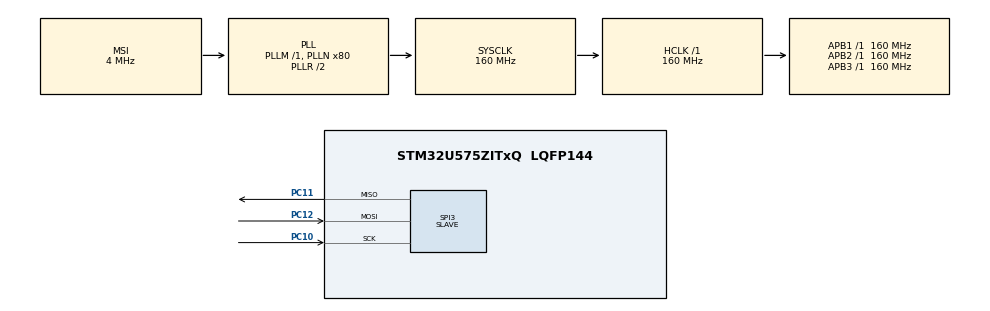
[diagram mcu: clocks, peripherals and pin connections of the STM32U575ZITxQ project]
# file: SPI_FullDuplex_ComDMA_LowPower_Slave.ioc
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CORTEX_M33_NS.userName=CORTEX_M33
LPDMA1.LINKALLOCATEDPORT_LPDMACH0=DMA_LINK_ALLOCATED_PORT1
LPDMA1.LINKALLOCATEDPORT_LPDMACH1=DMA_LINK_ALLOCATED_PORT1
LPDMA1.PRIORITY_LL_LPDMACH0=DMA_LOW_PRIORITY_HIGH_WEIGHT
LPDMA1.PRIORITY_LL_LPDMACH1=DMA_LOW_PRIORITY_HIGH_WEIGHT
Linkedlist.MDMA_Channel0.GP_SW.0.BlkHWRequest=DMA_BREQ_SINGLE_BURST
Linkedlist.MDMA_Channel0.GP_SW.0.DataHandling=NONE
Linkedlist.MDMA_Channel0.GP_SW.0.DataSize=0
Linkedlist.MDMA_Channel0.GP_SW.0.DestDataWidth=DMA_DEST_DATAWIDTH_BYTE
Linkedlist.MDMA_Channel0.GP_SW.0.DestInc=DMA_DINC_FIXED
Linkedlist.MDMA_Channel0.GP_SW.0.Direction=DMA_MEMORY_TO_PERIPH
Linkedlist.MDMA_Channel0.GP_SW.0.DstAddress=0
Linkedlist.MDMA_Channel0.GP_SW.0.Instance=MDMA_Channel0
Linkedlist.MDMA_Channel0.GP_SW.0.LL_MASTERDMA=LPDMA
Linkedlist.MDMA_Channel0.GP_SW.0.LL_NAME=Queue_tx
Linkedlist.MDMA_Channel0.GP_SW.0.LL_TYPE=LINEAR
Linkedlist.MDMA_Channel0.GP_SW.0.NODE_NAME=Node_tx
Linkedlist.MDMA_Channel0.GP_SW.0.Requestforcodegen=LPDMA1_REQUEST_SPI3_TX
Linkedlist.MDMA_Channel0.GP_SW.0.SrcAddress=0
Linkedlist.MDMA_Channel0.GP_SW.0.SrcDataWidth=DMA_SRC_DATAWIDTH_BYTE
Linkedlist.MDMA_Channel0.GP_SW.0.SrcInc=DMA_SINC_INCREMENTED
Linkedlist.MDMA_Channel0.GP_SW.0.TransferEventMode=DMA_TCEM_BLOCK_TRANSFER
Linkedlist.MDMA_Channel0.GP_SW.0.TriggerPolarity=DMA_TRIG_POLARITY_MASKED
Linkedlist.MDMA_Channel0.Request0=GP_SW
Linkedlist.MDMA_Channel0.RequestsNb=1
Linkedlist.MDMA_Channel1.GP_SW.0.BlkHWRequest=DMA_BREQ_SINGLE_BURST
Linkedlist.MDMA_Channel1.GP_SW.0.DataHandling=NONE
Linkedlist.MDMA_Channel1.GP_SW.0.DataSize=0
Linkedlist.MDMA_Channel1.GP_SW.0.DestDataWidth=DMA_DEST_DATAWIDTH_BYTE
Linkedlist.MDMA_Channel1.GP_SW.0.DestInc=DMA_DINC_INCREMENTED
Linkedlist.MDMA_Channel1.GP_SW.0.Direction=DMA_PERIPH_TO_MEMORY
Linkedlist.MDMA_Channel1.GP_SW.0.DstAddress=0
Linkedlist.MDMA_Channel1.GP_SW.0.Instance=MDMA_Channel1
Linkedlist.MDMA_Channel1.GP_SW.0.LL_MASTERDMA=LPDMA
Linkedlist.MDMA_Channel1.GP_SW.0.LL_NAME=Queue_rx
Linkedlist.MDMA_Channel1.GP_SW.0.LL_TYPE=LINEAR
Linkedlist.MDMA_Channel1.GP_SW.0.NODE_NAME=Node_rx
Linkedlist.MDMA_Channel1.GP_SW.0.Requestforcodegen=LPDMA1_REQUEST_SPI3_RX
Linkedlist.MDMA_Channel1.GP_SW.0.SrcAddress=0
Linkedlist.MDMA_Channel1.GP_SW.0.SrcDataWidth=DMA_SRC_DATAWIDTH_BYTE
Linkedlist.MDMA_Channel1.GP_SW.0.SrcInc=DMA_SINC_FIXED
Linkedlist.MDMA_Channel1.GP_SW.0.TransferEventMode=DMA_TCEM_BLOCK_TRANSFER
Linkedlist.MDMA_Channel1.GP_SW.0.TriggerPolarity=DMA_TRIG_POLARITY_MASKED
Linkedlist.MDMA_Channel1.Request0=GP_SW
Linkedlist.MDMA_Channel1.RequestsNb=1
Linkedlist.RequestSet0=MDMA_Channel0
Linkedlist.RequestSet1=MDMA_Channel1
Linkedlist.RequestSetsNb=2
Mcu.Family=STM32U5
Mcu.Name=STM32U575ZITxQ
Mcu.Package=LQFP144
NVIC.LPDMA1_Channel0_IRQn=true\:0\:0\:false\:false\:true\:true\:true\:true
NVIC.LPDMA1_Channel1_IRQn=true\:0\:0\:false\:false\:true\:true\:true\:true
NVIC.PriorityGroup=NVIC_PRIORITYGROUP_4
NVIC.SPI3_IRQn=true\:0\:0\:false\:false\:true\:true\:true\:true
PC10.Mode=Full_Duplex_Slave
PC10.Signal=SPI3_SCK
PC11.Mode=Full_Duplex_Slave
PC11.Signal=SPI3_MISO
PC12.Mode=Full_Duplex_Slave
PC12.Signal=SPI3_MOSI
PWR.PowerMode=PWR_SMPS_SUPPLY
ProjectManager.HeapSize=0x200
ProjectManager.StackSize=0x400
ProjectManager.TargetToolchain=EWARM V8.50
RCC.ADCFreq_Value=16000000
RCC.AHBFreq_Value=160000000
RCC.APB1Freq_Value=160000000
RCC.APB1TimFreq_Value=160000000
RCC.APB2Freq_Value=160000000
RCC.APB2TimFreq_Value=160000000
RCC.APB3Freq_Value=160000000
RCC.CortexFreq_Value=160000000
RCC.DACCLockSelectionVirtual=RCC_DAC1CLKSOURCE_LSI
RCC.DACCLockSelectionVirtualString=RCC_DAC1CLKSOURCE_LSI
RCC.EPOD_VALUE=4000000
RCC.HCLKFreq_Value=160000000
RCC.HSE_VALUE=16000000
RCC.HSI48_VALUE=48000000
RCC.HSI_VALUE=16000000
RCC.LSE_VALUE=32768
RCC.LSIDIV_VALUE=32000
RCC.MSI_VALUE=4000000
RCC.PLLN=80
RCC.SPI3CLockSelection=RCC_SPI3CLKSOURCE_HSI
RCC.SYSCLKFreq_VALUE=160000000
RCC.SYSCLKSource=RCC_SYSCLKSOURCE_PLLCLK
RCC.USBFreq_Value=48000000
RCC.VCOOutputFreq_Value=320000000
SPI3.DataSize=SPI_DATASIZE_8BIT
SPI3.Direction=SPI_DIRECTION_2LINES
SPI3.Mode=SPI_MODE_SLAVE
SPI3.VirtualType=VM_SLAVE
VP_ICACHE_VS_ICACHE.Mode=DirectMappedCache
VP_LPBAMQUEUE_VS_QUEUE.Mode=QUEUEMODE
VP_LPBAM_VS_SIG1.Mode=SmartRun
VP_LPBAM_VS_SIG4.Mode=LPDMA1
VP_LPDMA1_VS_LPDMACH0.Mode=LINKEDLIST_LPDMACH0
VP_LPDMA1_VS_LPDMACH1.Mode=LINKEDLIST_LPDMACH1
VP_PWR_VS_DBSignals.Mode=DisableDeadBatterySignals
VP_PWR_VS_LPOM.Mode=PowerOptimisation
VP_PWR_VS_SECSignals.Mode=Security/Privilege
board=custom

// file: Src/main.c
/* USER CODE BEGIN Header */
/**
  ******************************************************************************
  * @file           : main.c
  * @brief          : Main program body
  ******************************************************************************
  * @attention
  *
  * Copyright (c) 2021 STMicroelectronics.
  * All rights reserved.
  *
  * This software is licensed under terms that can be found in the LICENSE file
  * in the root directory of this software component.
  * If no LICENSE file comes with this software, it is provided AS-IS.
  *
  ******************************************************************************
  */
/* USER CODE END Header */
#include "main.h"

/* USER CODE BEGIN PTD */
enum {
	TRANSFER_WAIT,
	TRANSFER_COMPLETE,
	TRANSFER_ERROR
};
/* USER CODE END PTD */

/* USER CODE BEGIN PD */
uint8_t aTxBuffer[] = "****SPI - Two Boards communication based on DMA **** SPI Message ******** SPI Message ******** SPI Message ****";

/* Buffer used for reception */
#define BUFFER_ALIGNED_SIZE (((BUFFERSIZE+31)/32)*32)
ALIGN_32BYTES(uint8_t aRxBuffer[BUFFER_ALIGNED_SIZE]);

/* transfer state */
__IO uint32_t wTransferState = TRANSFER_WAIT;
/* USER CODE END PD */

DMA_HandleTypeDef handle_LPDMA1_Channel0;
DMA_HandleTypeDef handle_LPDMA1_Channel1;

SPI_HandleTypeDef hspi3;

void SystemClock_Config(void);
static void SystemPower_Config(void);
static void MX_GPIO_Init(void);
static void MX_LPDMA1_Init(void);
static void MX_ICACHE_Init(void);
static void MX_SPI3_Init(void);
/* USER CODE BEGIN PFP */
static uint16_t Buffercmp(uint8_t *pBuffer1, uint8_t *pBuffer2, uint16_t BufferLength);
/* USER CODE END PFP */

int main(void)
{

  /* USER CODE BEGIN 1 */
  /* STM32U5xx HAL library initialization:
       - Configure the Flash prefetch
       - Configure the Systick to generate an interrupt each 1 msec
       - Set NVIC Group Priority to 3
       - Low Level Initialization
     */
  /* USER CODE END 1 */

  /* MCU Configuration--------------------------------------------------------*/

  /* Reset of all peripherals, Initializes the Flash interface and the Systick. */
  HAL_Init();

  /* Configure the System Power */
  SystemPower_Config();

  /* Configure the system clock */
  SystemClock_Config();

  /* USER CODE BEGIN SysInit */
  /* Configure LED1, LED2 and LED3 */
  BSP_LED_Init(LED1);
  BSP_LED_Init(LED2);
  BSP_LED_Init(LED3);
  /* USER CODE END SysInit */

  /* Initialize all configured peripherals */
  MX_GPIO_Init();
  MX_LPDMA1_Init();
  MX_ICACHE_Init();
  MX_SPI3_Init();
  /* USER CODE BEGIN 2 */
  MX_Queue_tx_Config();
  HAL_DMAEx_List_LinkQ(&handle_LPDMA1_Channel1, &Queue_tx);
  __HAL_LINKDMA(&hspi3, hdmatx, handle_LPDMA1_Channel1);
  MX_Queue_rx_Config();
  HAL_DMAEx_List_LinkQ(&handle_LPDMA1_Channel0, &Queue_rx);
  __HAL_LINKDMA(&hspi3, hdmarx, handle_LPDMA1_Channel0);

  /*##-2- Start the Full Duplex Communication process ########################*/
  /* While the SPI in TransmitReceive process, user can transmit data through
     "aTxBuffer" buffer & receive data through "aRxBuffer" */
  if(HAL_SPI_TransmitReceive_DMA(&hspi3, (uint8_t*)aTxBuffer, (uint8_t *)aRxBuffer, BUFFERSIZE) != HAL_OK)
  {
    /* Transfer error in transmission process */
    Error_Handler();
  }

  /* Disable the SPI Error Interrupt Bit */
  __HAL_SPI_DISABLE_IT(&hspi3, (SPI_IT_OVR | SPI_IT_UDR | SPI_IT_FRE | SPI_IT_MODF));

  /* Enable the SPI End Of transfer Interrupt Bit */
  __HAL_SPI_ENABLE_IT(&hspi3, SPI_IT_EOT);

  /* Enter the system to stop 2 mode */
  HAL_PWREx_EnterSTOP2Mode(PWR_STOPENTRY_WFE);

  /* Check that the system was resumed from stop 2 */
  if ((READ_BIT(PWR->CR1, PWR_CR1_LPMS) != PWR_CR1_LPMS_1) || \
    (__HAL_PWR_GET_FLAG(PWR_FLAG_STOPF) == 0U))
  {
    while(1); /* KO */
  }
  /* Clear stop flag */
  __HAL_PWR_CLEAR_FLAG(PWR_FLAG_STOPF);

  /* Check that stop flag is cleared */
  if (__HAL_PWR_GET_FLAG(PWR_FLAG_STOPF) != 0U)
  {
    while(1); /* KO */
  }

  /*##-3- Wait for the end of the transfer ###################################*/
  /*  Before starting a new communication transfer, you must wait the callback call
      to get the transfer complete confirmation or an error detection.
      For simplicity reasons, this example is just waiting till the end of the
      transfer, but application may perform other tasks while transfer operation
      is ongoing. */
  while (wTransferState == TRANSFER_WAIT)
  {
  }

  switch(wTransferState)
  {
    case TRANSFER_COMPLETE :
      /*##-4- Compare the sent and received buffers ##############################*/
      if(Buffercmp((uint8_t*)aTxBuffer, (uint8_t*)aRxBuffer, BUFFERSIZE))
      {
        /* Processing Error */
        Error_Handler();
      }
    break;
    default :
      Error_Handler();
    break;
  }
  /* USER CODE END 2 */

  /* Infinite loop */
  while (1)
  {

  }
}

void SystemClock_Config(void)
{
  RCC_OscInitTypeDef RCC_OscInitStruct = {0};
  RCC_ClkInitTypeDef RCC_ClkInitStruct = {0};

  /** Configure the main internal regulator output voltage
  */
  if (HAL_PWREx_ControlVoltageScaling(PWR_REGULATOR_VOLTAGE_SCALE1) != HAL_OK)
  {
    Error_Handler();
  }

  /** Initializes the CPU, AHB and APB buses clocks
  */
  RCC_OscInitStruct.OscillatorType = RCC_OSCILLATORTYPE_HSI|RCC_OSCILLATORTYPE_MSI;
  RCC_OscInitStruct.HSIState = RCC_HSI_ON;
  RCC_OscInitStruct.HSICalibrationValue = RCC_HSICALIBRATION_DEFAULT;
  RCC_OscInitStruct.MSIState = RCC_MSI_ON;
  RCC_OscInitStruct.MSICalibrationValue = RCC_MSICALIBRATION_DEFAULT;
  RCC_OscInitStruct.MSIClockRange = RCC_MSIRANGE_4;
  RCC_OscInitStruct.PLL.PLLState = RCC_PLL_ON;
  RCC_OscInitStruct.PLL.PLLSource = RCC_PLLSOURCE_MSI;
  RCC_OscInitStruct.PLL.PLLMBOOST = RCC_PLLMBOOST_DIV1;
  RCC_OscInitStruct.PLL.PLLM = 1;
  RCC_OscInitStruct.PLL.PLLN = 80;
  RCC_OscInitStruct.PLL.PLLP = 2;
  RCC_OscInitStruct.PLL.PLLQ = 2;
  RCC_OscInitStruct.PLL.PLLR = 2;
  RCC_OscInitStruct.PLL.PLLRGE = RCC_PLLVCIRANGE_0;
  RCC_OscInitStruct.PLL.PLLFRACN = 0;
  if (HAL_RCC_OscConfig(&RCC_OscInitStruct) != HAL_OK)
  {
    Error_Handler();
  }

  /** Initializes the CPU, AHB and APB buses clocks
  */
  RCC_ClkInitStruct.ClockType = RCC_CLOCKTYPE_HCLK|RCC_CLOCKTYPE_SYSCLK
                              |RCC_CLOCKTYPE_PCLK1|RCC_CLOCKTYPE_PCLK2
                              |RCC_CLOCKTYPE_PCLK3;
  RCC_ClkInitStruct.SYSCLKSource = RCC_SYSCLKSOURCE_PLLCLK;
  RCC_ClkInitStruct.AHBCLKDivider = RCC_SYSCLK_DIV1;
  RCC_ClkInitStruct.APB1CLKDivider = RCC_HCLK_DIV1;
  RCC_ClkInitStruct.APB2CLKDivider = RCC_HCLK_DIV1;
  RCC_ClkInitStruct.APB3CLKDivider = RCC_HCLK_DIV1;

  if (HAL_RCC_ClockConfig(&RCC_ClkInitStruct, FLASH_LATENCY_4) != HAL_OK)
  {
    Error_Handler();
  }
}

/**
  * @brief Power Configuration
  * @retval None
  */
static void SystemPower_Config(void)
{

  /*
   * Disable the internal Pull-Up in Dead Battery pins of UCPD peripheral
   */
  HAL_PWREx_DisableUCPDDeadBattery();

  /*
   * Switch to SMPS regulator instead of LDO
   */
  if (HAL_PWREx_ConfigSupply(PWR_SMPS_SUPPLY) != HAL_OK)
  {
    Error_Handler();
  }
}

static void MX_ICACHE_Init(void)
{

  /** Enable instruction cache in 1-way (direct mapped cache)
  */
  if (HAL_ICACHE_ConfigAssociativityMode(ICACHE_1WAY) != HAL_OK)
  {
    Error_Handler();
  }
  if (HAL_ICACHE_Enable() != HAL_OK)
  {
    Error_Handler();
  }

}

static void MX_LPDMA1_Init(void)
{

  /* USER CODE BEGIN LPDMA1_Init 0 */
    DMAx_CLKAM_ENABLE();
    DMAx_CLK_SLEEP_ENABLE();
  /* USER CODE END LPDMA1_Init 0 */

  /* Peripheral clock enable */
  __HAL_RCC_LPDMA1_CLK_ENABLE();

  /* LPDMA1 interrupt Init */
    HAL_NVIC_SetPriority(LPDMA1_Channel0_IRQn, 0, 0);
    HAL_NVIC_EnableIRQ(LPDMA1_Channel0_IRQn);
    HAL_NVIC_SetPriority(LPDMA1_Channel1_IRQn, 0, 0);
    HAL_NVIC_EnableIRQ(LPDMA1_Channel1_IRQn);

  handle_LPDMA1_Channel0.Instance = LPDMA1_Channel0;
  handle_LPDMA1_Channel0.InitLinkedList.Priority = DMA_LOW_PRIORITY_HIGH_WEIGHT;
  handle_LPDMA1_Channel0.InitLinkedList.LinkStepMode = DMA_LSM_FULL_EXECUTION;
  handle_LPDMA1_Channel0.InitLinkedList.LinkAllocatedPort = DMA_LINK_ALLOCATED_PORT1;
  handle_LPDMA1_Channel0.InitLinkedList.TransferEventMode = DMA_TCEM_LAST_LL_ITEM_TRANSFER;
  handle_LPDMA1_Channel0.InitLinkedList.LinkedListMode = DMA_LINKEDLIST_NORMAL;
  if (HAL_DMAEx_List_Init(&handle_LPDMA1_Channel0) != HAL_OK)
  {
    Error_Handler();
  }
  if (HAL_DMA_ConfigChannelAttributes(&handle_LPDMA1_Channel0, DMA_CHANNEL_NPRIV) != HAL_OK)
  {
    Error_Handler();
  }
  handle_LPDMA1_Channel1.Instance = LPDMA1_Channel1;
  handle_LPDMA1_Channel1.InitLinkedList.Priority = DMA_LOW_PRIORITY_HIGH_WEIGHT;
  handle_LPDMA1_Channel1.InitLinkedList.LinkStepMode = DMA_LSM_FULL_EXECUTION;
  handle_LPDMA1_Channel1.InitLinkedList.LinkAllocatedPort = DMA_LINK_ALLOCATED_PORT1;
  handle_LPDMA1_Channel1.InitLinkedList.TransferEventMode = DMA_TCEM_LAST_LL_ITEM_TRANSFER;
  handle_LPDMA1_Channel1.InitLinkedList.LinkedListMode = DMA_LINKEDLIST_NORMAL;
  if (HAL_DMAEx_List_Init(&handle_LPDMA1_Channel1) != HAL_OK)
  {
    Error_Handler();
  }
  if (HAL_DMA_ConfigChannelAttributes(&handle_LPDMA1_Channel1, DMA_CHANNEL_NPRIV) != HAL_OK)
  {
    Error_Handler();
  }

}

static void MX_SPI3_Init(void)
{

  SPI_AutonomousModeConfTypeDef HAL_SPI_AutonomousMode_Cfg_Struct = {0};

  /* SPI3 parameter configuration*/
  hspi3.Instance = SPI3;
  hspi3.Init.Mode = SPI_MODE_SLAVE;
  hspi3.Init.Direction = SPI_DIRECTION_2LINES;
  hspi3.Init.DataSize = SPI_DATASIZE_8BIT;
  hspi3.Init.CLKPolarity = SPI_POLARITY_LOW;
  hspi3.Init.CLKPhase = SPI_PHASE_1EDGE;
  hspi3.Init.NSS = SPI_NSS_SOFT;
  hspi3.Init.FirstBit = SPI_FIRSTBIT_MSB;
  hspi3.Init.TIMode = SPI_TIMODE_DISABLE;
  hspi3.Init.CRCCalculation = SPI_CRCCALCULATION_DISABLE;
  hspi3.Init.CRCPolynomial = 0x7;
  hspi3.Init.NSSPMode = SPI_NSS_PULSE_DISABLE;
  hspi3.Init.NSSPolarity = SPI_NSS_POLARITY_LOW;
  hspi3.Init.FifoThreshold = SPI_FIFO_THRESHOLD_01DATA;
  hspi3.Init.MasterSSIdleness = SPI_MASTER_SS_IDLENESS_00CYCLE;
  hspi3.Init.MasterInterDataIdleness = SPI_MASTER_INTERDATA_IDLENESS_00CYCLE;
  hspi3.Init.MasterReceiverAutoSusp = SPI_MASTER_RX_AUTOSUSP_DISABLE;
  hspi3.Init.MasterKeepIOState = SPI_MASTER_KEEP_IO_STATE_DISABLE;
  hspi3.Init.IOSwap = SPI_IO_SWAP_DISABLE;
  hspi3.Init.ReadyMasterManagement = SPI_RDY_MASTER_MANAGEMENT_INTERNALLY;
  hspi3.Init.ReadyPolarity = SPI_RDY_POLARITY_HIGH;
  if (HAL_SPI_Init(&hspi3) != HAL_OK)
  {
    Error_Handler();
  }
  HAL_SPI_AutonomousMode_Cfg_Struct.TriggerState = SPI_AUTO_MODE_DISABLE;
  HAL_SPI_AutonomousMode_Cfg_Struct.TriggerSelection = SPI_GRP2_LPDMA_CH0_TCF_TRG;
  HAL_SPI_AutonomousMode_Cfg_Struct.TriggerPolarity = SPI_TRIG_POLARITY_RISING;
  if (HAL_SPIEx_SetConfigAutonomousMode(&hspi3, &HAL_SPI_AutonomousMode_Cfg_Struct) != HAL_OK)
  {
    Error_Handler();
  }

}

static void MX_GPIO_Init(void)
{

  /* GPIO Ports Clock Enable */
  __HAL_RCC_GPIOC_CLK_ENABLE();

}

/* USER CODE BEGIN 4 */
/**
  * @brief  TxRx Transfer completed callback.
  * @param  hspi: SPI handle
  * @note   This example shows a simple way to report end of DMA TxRx transfer, and
  *         you can add your own implementation.
  * @retval None
  */
void HAL_SPI_TxRxCpltCallback(SPI_HandleTypeDef *hspi)
{
  /* Turn LED1 on: Transfer in transmission process is complete */
  BSP_LED_On(LED1);
  /* Turn LED2 on: Transfer in reception process is complete */
  BSP_LED_On(LED2);
  wTransferState = TRANSFER_COMPLETE;
}

/**
  * @brief  SPI error callbacks.
  * @param  hspi: SPI handle
  * @note   This example shows a simple way to report transfer error, and you can
  *         add your own implementation.
  * @retval None
  */
void HAL_SPI_ErrorCallback(SPI_HandleTypeDef *hspi)
{
  wTransferState = TRANSFER_ERROR;
}

/**
  * @brief  Compares two buffers.
  * @param  pBuffer1, pBuffer2: buffers to be compared.
  * @param  BufferLength: buffer's length
  * @retval 0  : pBuffer1 identical to pBuffer2
  *         >0 : pBuffer1 differs from pBuffer2
  */
static uint16_t Buffercmp(uint8_t *pBuffer1, uint8_t *pBuffer2, uint16_t BufferLength)
{
  while (BufferLength--)
  {
    if((*pBuffer1) != *pBuffer2)
    {
      return BufferLength;
    }
    pBuffer1++;
    pBuffer2++;
  }

  return 0;
}
/* USER CODE END 4 */

void Error_Handler(void)
{
  /* USER CODE BEGIN Error_Handler_Debug */
  /* User can add his own implementation to report the HAL error return state */
  /* Turn LED1 off */
  BSP_LED_Off(LED1);
  /* Turn LED3 on */
  BSP_LED_On(LED3);
  while(1)
  {
  }
  /* USER CODE END Error_Handler_Debug */
}
